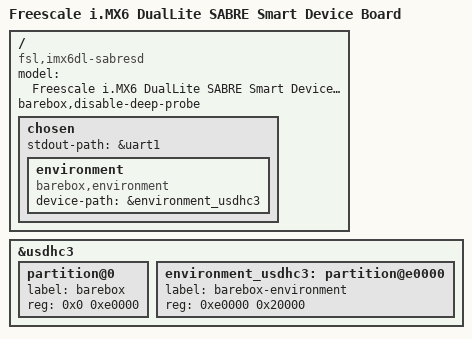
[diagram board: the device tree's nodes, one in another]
/*
 * Copyright 2012 Freescale Semiconductor, Inc.
 * Copyright 2011 Linaro Ltd.
 *
 * The code contained herein is licensed under the GNU General Public
 * License. You may obtain a copy of the GNU General Public License
 * Version 2 or later at the following locations:
 *
 * http://www.opensource.org/licenses/gpl-license.html
 * http://www.gnu.org/copyleft/gpl.html
 */

#include <arm/nxp/imx/imx6dl-sabresd.dts>

/ {
	model = "Freescale i.MX6 DualLite SABRE Smart Device Board";
	compatible = "fsl,imx6dl-sabresd", "fsl,imx6dl";
	barebox,disable-deep-probe;

	chosen {
		stdout-path = &uart1;

		environment {
			compatible = "barebox,environment";
			device-path = &environment_usdhc3;
		};
	};
};

&usdhc3 {
	#address-cells = <1>;
	#size-cells = <1>;

	partition@0 {
		label = "barebox";
		reg = <0x0 0xe0000>;
	};

	environment_usdhc3: partition@e0000 {
		label = "barebox-environment";
		reg = <0xe0000 0x20000>;
	};
};
